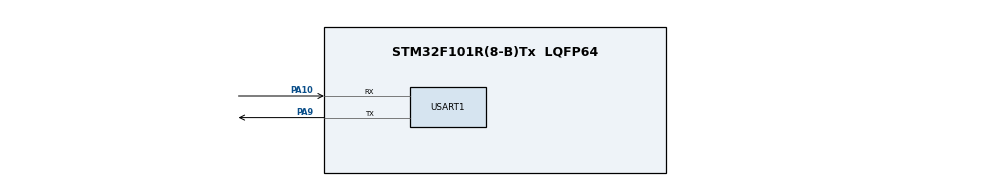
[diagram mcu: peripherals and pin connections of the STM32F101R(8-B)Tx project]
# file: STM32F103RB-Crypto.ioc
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Mcu.Family=STM32F1
Mcu.Name=STM32F101R(8-B)Tx
Mcu.Package=LQFP64
NVIC.PriorityGroup=NVIC_PRIORITYGROUP_4
PA10.Mode=Asynchronous
PA10.Signal=USART1_RX
PA13.Mode=Serial_Wire
PA13.Signal=SYS_JTMS-SWDIO
PA14.Mode=Serial_Wire
PA14.Signal=SYS_JTCK-SWCLK
PA9.Mode=Asynchronous
PA9.Signal=USART1_TX
ProjectManager.HeapSize=0x200
ProjectManager.StackSize=0x400
ProjectManager.TargetToolchain=STM32CubeIDE
RCC.APB1Freq_Value=8000000
RCC.APB2Freq_Value=8000000
USART1.VirtualMode=VM_ASYNC
VP_CRC_VS_CRC.Mode=CRC_Activate
board=custom

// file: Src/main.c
/* USER CODE BEGIN Header */
/** Mosallaei Mostafa commit
  ******************************************************************************
  * @file           : main.c
  * @brief          : Main program body
  ******************************************************************************
  * @attention
  *
  * <h2><center>&copy; Copyright (c) 2019 STMicroelectronics.
  * All rights reserved.</center></h2>
  *
  * This software component is licensed by ST under BSD 3-Clause license,
  * the "License"; You may not use this file except in compliance with the
  * License. You may obtain a copy of the License at:
  *                        opensource.org/licenses/BSD-3-Clause
  *
  ******************************************************************************
  */
/* USER CODE END Header */

#include "main.h"

/* USER CODE BEGIN Includes */

/* Private typedef -----------------------------------------------------------*/
typedef enum {FAILED = 0, PASSED = !FAILED} TestStatus;
/* Private define ------------------------------------------------------------*/
#define PLAINTEXT_LENGTH 64
/* Private macro -------------------------------------------------------------*/
/* Private variables ---------------------------------------------------------*/
const uint8_t Plaintext[PLAINTEXT_LENGTH] =
  {
    0x6b, 0xc1, 0xbe, 0xe2, 0x2e, 0x40, 0x9f, 0x96,
    0xe9, 0x3d, 0x7e, 0x11, 0x73, 0x93, 0x17, 0x2a,
    0xae, 0x2d, 0x8a, 0x57, 0x1e, 0x03, 0xac, 0x9c,
    0x9e, 0xb7, 0x6f, 0xac, 0x45, 0xaf, 0x8e, 0x51,
    0x30, 0xc8, 0x1c, 0x46, 0xa3, 0x5c, 0xe4, 0x11,
    0xe5, 0xfb, 0xc1, 0x19, 0x1a, 0x0a, 0x52, 0xef,
    0xf6, 0x9f, 0x24, 0x45, 0xdf, 0x4f, 0x9b, 0x17,
    0xad, 0x2b, 0x41, 0x7b, 0xe6, 0x6c, 0x37, 0x10
  };

/* Key to be used for AES encryption/decryption */
uint8_t Key[CRL_AES192_KEY] =
  {
    0x8e, 0x73, 0xb0, 0xf7, 0xda, 0x0e, 0x64, 0x52,
    0xc8, 0x10, 0xf3, 0x2b, 0x80, 0x90, 0x79, 0xe5,
    0x62, 0xf8, 0xea, 0xd2, 0x52, 0x2c, 0x6b, 0x7b,
  };

/* Initialization Vector */
uint8_t IV[CRL_AES_BLOCK] =
  {
    0x00, 0x01, 0x02, 0x03, 0x04, 0x05, 0x06, 0x07,
    0x08, 0x09, 0x0a, 0x0b, 0x0c, 0x0d, 0x0e, 0x0f
  };

/* Buffer to store the output data */
uint8_t OutputMessage[PLAINTEXT_LENGTH];

/* Size of the output data */
uint32_t OutputMessageLength = 0;

const uint8_t Expected_Ciphertext[PLAINTEXT_LENGTH] =
  {
    0x4f, 0x02, 0x1d, 0xb2, 0x43, 0xbc, 0x63, 0x3d,
    0x71, 0x78, 0x18, 0x3a, 0x9f, 0xa0, 0x71, 0xe8,
    0xb4, 0xd9, 0xad, 0xa9, 0xad, 0x7d, 0xed, 0xf4,
    0xe5, 0xe7, 0x38, 0x76, 0x3f, 0x69, 0x14, 0x5a,
    0x57, 0x1b, 0x24, 0x20, 0x12, 0xfb, 0x7a, 0xe0,
    0x7f, 0xa9, 0xba, 0xac, 0x3d, 0xf1, 0x02, 0xe0,
    0x08, 0xb0, 0xe2, 0x79, 0x88, 0x59, 0x88, 0x81,
    0xd9, 0x20, 0xa9, 0xe6, 0x4f, 0x56, 0x15, 0xcd,
  };

/* Private function prototypes -----------------------------------------------*/
int32_t STM32_AES_CBC_Encrypt(uint8_t*  InputMessage,
                              uint32_t  InputMessageLength,
                              uint8_t  *AES192_Key,
                              uint8_t  *InitializationVector,
                              uint32_t  IvLength,
                              uint8_t  *OutputMessage,
                              uint32_t *OutputMessageLength);

int32_t STM32_AES_CBC_Decrypt(uint8_t*  InputMessage,
                              uint32_t  InputMessageLength,
                              uint8_t  *AES192_Key,
                              uint8_t  *InitializationVector,
                              uint32_t  IvLength,
                              uint8_t  *OutputMessage,
                              uint32_t *OutputMessageLength);

TestStatus Buffercmp(const uint8_t* pBuffer,
                     uint8_t* pBuffer1,
                     uint16_t BufferLength);

static void SystemClock_Config(void);
//static void Led_Config(void);
//static void Led_Toggle( __IO uint32_t toggle_delay);
//static void Error_Handler(void);
/* USER CODE END Includes */

CRC_HandleTypeDef hcrc;

UART_HandleTypeDef huart1;

void SystemClock_Config(void);
static void MX_GPIO_Init(void);
static void MX_CRC_Init(void);
static void MX_USART1_UART_Init(void);

int main(void)
{
  /* USER CODE BEGIN 1 */

	  int32_t status = AES_SUCCESS;
  /* USER CODE END 1 */

  /* MCU Configuration--------------------------------------------------------*/

  /* Reset of all peripherals, Initializes the Flash interface and the Systick. */
  HAL_Init();

  /* Configure the system clock */
  SystemClock_Config();

  /* Initialize all configured peripherals */
  MX_GPIO_Init();
  MX_CRC_Init();
  MX_USART1_UART_Init();
  /* USER CODE BEGIN 2 */

  /* Encrypt DATA with AES in CBC mode */
  status = STM32_AES_CBC_Encrypt( (uint8_t *) Plaintext, PLAINTEXT_LENGTH, Key, IV, sizeof(IV), OutputMessage, &OutputMessageLength);

  /* USER CODE END 2 */

  /* Infinite loop */
  while (1)
  {

  }
}

void SystemClock_Config(void)
{
  RCC_OscInitTypeDef RCC_OscInitStruct = {0};
  RCC_ClkInitTypeDef RCC_ClkInitStruct = {0};

  /** Initializes the CPU, AHB and APB busses clocks
  */
  RCC_OscInitStruct.OscillatorType = RCC_OSCILLATORTYPE_HSI;
  RCC_OscInitStruct.HSIState = RCC_HSI_ON;
  RCC_OscInitStruct.HSICalibrationValue = RCC_HSICALIBRATION_DEFAULT;
  RCC_OscInitStruct.PLL.PLLState = RCC_PLL_NONE;
  if (HAL_RCC_OscConfig(&RCC_OscInitStruct) != HAL_OK)
  {
    Error_Handler();
  }
  /** Initializes the CPU, AHB and APB busses clocks
  */
  RCC_ClkInitStruct.ClockType = RCC_CLOCKTYPE_HCLK|RCC_CLOCKTYPE_SYSCLK
                              |RCC_CLOCKTYPE_PCLK1|RCC_CLOCKTYPE_PCLK2;
  RCC_ClkInitStruct.SYSCLKSource = RCC_SYSCLKSOURCE_HSI;
  RCC_ClkInitStruct.AHBCLKDivider = RCC_SYSCLK_DIV1;
  RCC_ClkInitStruct.APB1CLKDivider = RCC_HCLK_DIV1;
  RCC_ClkInitStruct.APB2CLKDivider = RCC_HCLK_DIV1;

  if (HAL_RCC_ClockConfig(&RCC_ClkInitStruct, FLASH_LATENCY_0) != HAL_OK)
  {
    Error_Handler();
  }
}

static void MX_CRC_Init(void)
{

  hcrc.Instance = CRC;
  if (HAL_CRC_Init(&hcrc) != HAL_OK)
  {
    Error_Handler();
  }

}

static void MX_USART1_UART_Init(void)
{

  huart1.Instance = USART1;
  huart1.Init.BaudRate = 115200;
  huart1.Init.WordLength = UART_WORDLENGTH_8B;
  huart1.Init.StopBits = UART_STOPBITS_1;
  huart1.Init.Parity = UART_PARITY_NONE;
  huart1.Init.Mode = UART_MODE_TX_RX;
  huart1.Init.HwFlowCtl = UART_HWCONTROL_NONE;
  huart1.Init.OverSampling = UART_OVERSAMPLING_16;
  if (HAL_UART_Init(&huart1) != HAL_OK)
  {
    Error_Handler();
  }

}

static void MX_GPIO_Init(void)
{

  /* GPIO Ports Clock Enable */
  __HAL_RCC_GPIOA_CLK_ENABLE();

}

void Error_Handler(void)
{
}

/************************ (C) COPYRIGHT STMicroelectronics *****END OF FILE****/
